AUTOSAR XML (schema 4-3-0)
standard types defined: Boolean, UInt8, SInt8, UInt16, SInt16, UInt32, SInt32, boolean, uint8, sint8, uint16, sint16, uint32, sint32
package /Components
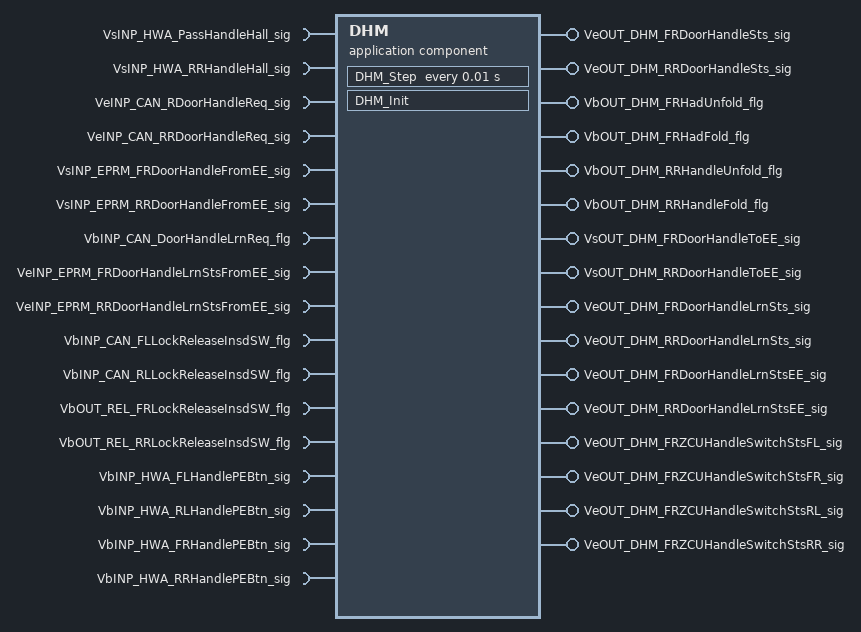
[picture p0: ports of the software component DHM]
  application sw component type DHM
    17 x require port:
      VsINP_HWA_PassHandleHall_sig: nonqueued-receiver-com-spec{data-element=VsINP_HWA_PassHandleHall_sig, init-value=0}, required-interface=VsINP_HWA_PassHandleHall_sig
      VsINP_HWA_RRHandleHall_sig: nonqueued-receiver-com-spec{data-element=VsINP_HWA_RRHandleHall_sig, init-value=0}, required-interface=VsINP_HWA_RRHandleHall_sig
      VeINP_CAN_RDoorHandleReq_sig: nonqueued-receiver-com-spec{data-element=VeINP_CAN_RDoorHandleReq_sig, init-value=0}, required-interface=VeINP_CAN_RDoorHandleReq_sig
      VeINP_CAN_RRDoorHandleReq_sig: nonqueued-receiver-com-spec{data-element=VeINP_CAN_RRDoorHandleReq_sig, init-value=0}, required-interface=VeINP_CAN_RRDoorHandleReq_sig
      VsINP_EPRM_FRDoorHandleFromEE_sig: nonqueued-receiver-com-spec{data-element=VsINP_EPRM_FRDoorHandleFromEE_sig, init-value=0}, required-interface=VsINP_EPRM_FRDoorHandleFromEE_sig
      VsINP_EPRM_RRDoorHandleFromEE_sig: nonqueued-receiver-com-spec{data-element=VsINP_EPRM_RRDoorHandleFromEE_sig, init-value=0}, required-interface=VsINP_EPRM_RRDoorHandleFromEE_sig
      VbINP_CAN_DoorHandleLrnReq_flg: nonqueued-receiver-com-spec{data-element=VbINP_CAN_DoorHandleLrnReq_flg, init-value=0}, required-interface=VbINP_CAN_DoorHandleLrnReq_flg
      VeINP_EPRM_FRDoorHandleLrnStsFromEE_sig: nonqueued-receiver-com-spec{data-element=VeINP_EPRM_FRDoorHandleLrnStsFromEE_sig, init-value=0}, required-interface=VeINP_EPRM_FRDoorHandleLrnStsFromEE_sig
      VeINP_EPRM_RRDoorHandleLrnStsFromEE_sig: nonqueued-receiver-com-spec{data-element=VeINP_EPRM_RRDoorHandleLrnStsFromEE_sig, init-value=0}, required-interface=VeINP_EPRM_RRDoorHandleLrnStsFromEE_sig
      VbINP_CAN_FLLockReleaseInsdSW_flg: nonqueued-receiver-com-spec{data-element=VbINP_CAN_FLLockReleaseInsdSW_flg, init-value=0}, required-interface=VbINP_CAN_FLLockReleaseInsdSW_flg
      VbINP_CAN_RLLockReleaseInsdSW_flg: nonqueued-receiver-com-spec{data-element=VbINP_CAN_RLLockReleaseInsdSW_flg, init-value=0}, required-interface=VbINP_CAN_RLLockReleaseInsdSW_flg
      VbOUT_REL_FRLockReleaseInsdSW_flg: nonqueued-receiver-com-spec{data-element=VbOUT_REL_FRLockReleaseInsdSW_flg, init-value=0}, required-interface=VbOUT_REL_FRLockReleaseInsdSW_flg
      VbOUT_REL_RRLockReleaseInsdSW_flg: nonqueued-receiver-com-spec{data-element=VbOUT_REL_RRLockReleaseInsdSW_flg, init-value=0}, required-interface=VbOUT_REL_RRLockReleaseInsdSW_flg
      VbINP_HWA_FLHandlePEBtn_sig: nonqueued-receiver-com-spec{data-element=VbINP_HWA_FLHandlePEBtn_sig, init-value=0}, required-interface=VbINP_HWA_FLHandlePEBtn_sig
      VbINP_HWA_RLHandlePEBtn_sig: nonqueued-receiver-com-spec{data-element=VbINP_HWA_RLHandlePEBtn_sig, init-value=0}, required-interface=VbINP_HWA_RLHandlePEBtn_sig
      VbINP_HWA_FRHandlePEBtn_sig: nonqueued-receiver-com-spec{data-element=VbINP_HWA_FRHandlePEBtn_sig, init-value=0}, required-interface=VbINP_HWA_FRHandlePEBtn_sig
      VbINP_HWA_RRHandlePEBtn_sig: nonqueued-receiver-com-spec{data-element=VbINP_HWA_RRHandlePEBtn_sig, init-value=0}, required-interface=VbINP_HWA_RRHandlePEBtn_sig
    16 x provide port:
      VeOUT_DHM_FRDoorHandleSts_sig: nonqueued-sender-com-spec{data-element=VeOUT_DHM_FRDoorHandleSts_sig, init-value=0}, provided-interface=VeOUT_DHM_FRDoorHandleSts_sig
      VeOUT_DHM_RRDoorHandleSts_sig: nonqueued-sender-com-spec{data-element=VeOUT_DHM_RRDoorHandleSts_sig, init-value=0}, provided-interface=VeOUT_DHM_RRDoorHandleSts_sig
      VbOUT_DHM_FRHadUnfold_flg: nonqueued-sender-com-spec{data-element=VbOUT_DHM_FRHadUnfold_flg, init-value=0}, provided-interface=VbOUT_DHM_FRHadUnfold_flg
      VbOUT_DHM_FRHadFold_flg: nonqueued-sender-com-spec{data-element=VbOUT_DHM_FRHadFold_flg, init-value=0}, provided-interface=VbOUT_DHM_FRHadFold_flg
      VbOUT_DHM_RRHandleUnfold_flg: nonqueued-sender-com-spec{data-element=VbOUT_DHM_RRHandleUnfold_flg, init-value=0}, provided-interface=VbOUT_DHM_RRHandleUnfold_flg
      VbOUT_DHM_RRHandleFold_flg: nonqueued-sender-com-spec{data-element=VbOUT_DHM_RRHandleFold_flg, init-value=0}, provided-interface=VbOUT_DHM_RRHandleFold_flg
      VsOUT_DHM_FRDoorHandleToEE_sig: nonqueued-sender-com-spec{data-element=VsOUT_DHM_FRDoorHandleToEE_sig, init-value=0}, provided-interface=VsOUT_DHM_FRDoorHandleToEE_sig
      VsOUT_DHM_RRDoorHandleToEE_sig: nonqueued-sender-com-spec{data-element=VsOUT_DHM_RRDoorHandleToEE_sig, init-value=0}, provided-interface=VsOUT_DHM_RRDoorHandleToEE_sig
      VeOUT_DHM_FRDoorHandleLrnSts_sig: nonqueued-sender-com-spec{data-element=VeOUT_DHM_FRDoorHandleLrnSts_sig, init-value=0}, provided-interface=VeOUT_DHM_FRDoorHandleLrnSts_sig
      VeOUT_DHM_RRDoorHandleLrnSts_sig: nonqueued-sender-com-spec{data-element=VeOUT_DHM_RRDoorHandleLrnSts_sig, init-value=0}, provided-interface=VeOUT_DHM_RRDoorHandleLrnSts_sig
      VeOUT_DHM_FRDoorHandleLrnStsEE_sig: nonqueued-sender-com-spec{data-element=VeOUT_DHM_FRDoorHandleLrnStsEE_sig, init-value=0}, provided-interface=VeOUT_DHM_FRDoorHandleLrnStsEE_sig
      VeOUT_DHM_RRDoorHandleLrnStsEE_sig: nonqueued-sender-com-spec{data-element=VeOUT_DHM_RRDoorHandleLrnStsEE_sig, init-value=0}, provided-interface=VeOUT_DHM_RRDoorHandleLrnStsEE_sig
      VeOUT_DHM_FRZCUHandleSwitchStsFL_sig: nonqueued-sender-com-spec{data-element=VeOUT_DHM_FRZCUHandleSwitchStsFL_sig, init-value=0}, provided-interface=VeOUT_DHM_FRZCUHandleSwitchStsFL_sig
      VeOUT_DHM_FRZCUHandleSwitchStsFR_sig: nonqueued-sender-com-spec{data-element=VeOUT_DHM_FRZCUHandleSwitchStsFR_sig, init-value=0}, provided-interface=VeOUT_DHM_FRZCUHandleSwitchStsFR_sig
      VeOUT_DHM_FRZCUHandleSwitchStsRL_sig: nonqueued-sender-com-spec{data-element=VeOUT_DHM_FRZCUHandleSwitchStsRL_sig, init-value=0}, provided-interface=VeOUT_DHM_FRZCUHandleSwitchStsRL_sig
      VeOUT_DHM_FRZCUHandleSwitchStsRR_sig: nonqueued-sender-com-spec{data-element=VeOUT_DHM_FRZCUHandleSwitchStsRR_sig, init-value=0}, provided-interface=VeOUT_DHM_FRZCUHandleSwitchStsRR_sig
    behavior DHM: data-type-mapping=DataTypeMappingsSet, handle-termination-and-restart=NO-SUPPORT
      init event DHM_InitEvent: start-on-event=DHM_Init
      timing event Event_Runnable_Step: start-on-event=DHM_Step, period=0.01
      runnable DHM_Init
      runnable DHM_Step
        data-receive-point-by-arguments:
          17 x access:
            IN_VsINP_HWA_PassHandleHall_sig_VsINP_HWA_PassHandleHall_sig: accessed-variable=VsINP_HWA_PassHandleHall_sig.VsINP_HWA_PassHandleHall_sig
            IN_VsINP_HWA_RRHandleHall_sig_VsINP_HWA_RRHandleHall_sig: accessed-variable=VsINP_HWA_RRHandleHall_sig.VsINP_HWA_RRHandleHall_sig
            IN_VeINP_CAN_RDoorHandleReq_sig_VeINP_CAN_RDoorHandleReq_sig: accessed-variable=VeINP_CAN_RDoorHandleReq_sig.VeINP_CAN_RDoorHandleReq_sig
            IN_VeINP_CAN_RRDoorHandleReq_sig_VeINP_CAN_RRDoorHandleReq_sig: accessed-variable=VeINP_CAN_RRDoorHandleReq_sig.VeINP_CAN_RRDoorHandleReq_sig
            IN_VsINP_EPRM_FRDoorHandleFromEE_sig_VsINP_EPRM_FRDoorHandleFromEE_sig: accessed-variable=VsINP_EPRM_FRDoorHandleFromEE_sig.VsINP_EPRM_FRDoorHandleFromEE_sig
            IN_VsINP_EPRM_RRDoorHandleFromEE_sig_VsINP_EPRM_RRDoorHandleFromEE_sig: accessed-variable=VsINP_EPRM_RRDoorHandleFromEE_sig.VsINP_EPRM_RRDoorHandleFromEE_sig
            IN_VbINP_CAN_DoorHandleLrnReq_flg_VbINP_CAN_DoorHandleLrnReq_flg: accessed-variable=VbINP_CAN_DoorHandleLrnReq_flg.VbINP_CAN_DoorHandleLrnReq_flg
            IN_VeINP_EPRM_FRDoorHandleLrnStsFromEE_sig_VeINP_EPRM_FRDoorHandleLrnStsFromEE_sig: accessed-variable=VeINP_EPRM_FRDoorHandleLrnStsFromEE_sig.VeINP_EPRM_FRDoorHandleLrnStsFromEE_sig
            IN_VeINP_EPRM_RRDoorHandleLrnStsFromEE_sig_VeINP_EPRM_RRDoorHandleLrnStsFromEE_sig: accessed-variable=VeINP_EPRM_RRDoorHandleLrnStsFromEE_sig.VeINP_EPRM_RRDoorHandleLrnStsFromEE_sig
            IN_VbINP_CAN_FLLockReleaseInsdSW_flg_VbINP_CAN_FLLockReleaseInsdSW_flg: accessed-variable=VbINP_CAN_FLLockReleaseInsdSW_flg.VbINP_CAN_FLLockReleaseInsdSW_flg
            IN_VbINP_CAN_RLLockReleaseInsdSW_flg_VbINP_CAN_RLLockReleaseInsdSW_flg: accessed-variable=VbINP_CAN_RLLockReleaseInsdSW_flg.VbINP_CAN_RLLockReleaseInsdSW_flg
            IN_VbOUT_REL_FRLockReleaseInsdSW_flg_VbOUT_REL_FRLockReleaseInsdSW_flg: accessed-variable=VbOUT_REL_FRLockReleaseInsdSW_flg.VbOUT_REL_FRLockReleaseInsdSW_flg
            IN_VbOUT_REL_RRLockReleaseInsdSW_flg_VbOUT_REL_RRLockReleaseInsdSW_flg: accessed-variable=VbOUT_REL_RRLockReleaseInsdSW_flg.VbOUT_REL_RRLockReleaseInsdSW_flg
            IN_VbINP_HWA_FLHandlePEBtn_sig_VbINP_HWA_FLHandlePEBtn_sig: accessed-variable=VbINP_HWA_FLHandlePEBtn_sig.VbINP_HWA_FLHandlePEBtn_sig
            IN_VbINP_HWA_RLHandlePEBtn_sig_VbINP_HWA_RLHandlePEBtn_sig: accessed-variable=VbINP_HWA_RLHandlePEBtn_sig.VbINP_HWA_RLHandlePEBtn_sig
            IN_VbINP_HWA_FRHandlePEBtn_sig_VbINP_HWA_FRHandlePEBtn_sig: accessed-variable=VbINP_HWA_FRHandlePEBtn_sig.VbINP_HWA_FRHandlePEBtn_sig
            IN_VbINP_HWA_RRHandlePEBtn_sig_VbINP_HWA_RRHandlePEBtn_sig: accessed-variable=VbINP_HWA_RRHandlePEBtn_sig.VbINP_HWA_RRHandlePEBtn_sig
        data-send-points:
          16 x access:
            OUT_VeOUT_DHM_FRDoorHandleSts_sig_VeOUT_DHM_FRDoorHandleSts_sig: accessed-variable=VeOUT_DHM_FRDoorHandleSts_sig.VeOUT_DHM_FRDoorHandleSts_sig
            OUT_VeOUT_DHM_RRDoorHandleSts_sig_VeOUT_DHM_RRDoorHandleSts_sig: accessed-variable=VeOUT_DHM_RRDoorHandleSts_sig.VeOUT_DHM_RRDoorHandleSts_sig
            OUT_VbOUT_DHM_FRHadUnfold_flg_VbOUT_DHM_FRHadUnfold_flg: accessed-variable=VbOUT_DHM_FRHadUnfold_flg.VbOUT_DHM_FRHadUnfold_flg
            OUT_VbOUT_DHM_FRHadFold_flg_VbOUT_DHM_FRHadFold_flg: accessed-variable=VbOUT_DHM_FRHadFold_flg.VbOUT_DHM_FRHadFold_flg
            OUT_VbOUT_DHM_RRHandleUnfold_flg_VbOUT_DHM_RRHandleUnfold_flg: accessed-variable=VbOUT_DHM_RRHandleUnfold_flg.VbOUT_DHM_RRHandleUnfold_flg
            OUT_VbOUT_DHM_RRHandleFold_flg_VbOUT_DHM_RRHandleFold_flg: accessed-variable=VbOUT_DHM_RRHandleFold_flg.VbOUT_DHM_RRHandleFold_flg
            OUT_VsOUT_DHM_FRDoorHandleToEE_sig_VsOUT_DHM_FRDoorHandleToEE_sig: accessed-variable=VsOUT_DHM_FRDoorHandleToEE_sig.VsOUT_DHM_FRDoorHandleToEE_sig
            OUT_VsOUT_DHM_RRDoorHandleToEE_sig_VsOUT_DHM_RRDoorHandleToEE_sig: accessed-variable=VsOUT_DHM_RRDoorHandleToEE_sig.VsOUT_DHM_RRDoorHandleToEE_sig
            OUT_VeOUT_DHM_FRDoorHandleLrnSts_sig_VeOUT_DHM_FRDoorHandleLrnSts_sig: accessed-variable=VeOUT_DHM_FRDoorHandleLrnSts_sig.VeOUT_DHM_FRDoorHandleLrnSts_sig
            OUT_VeOUT_DHM_RRDoorHandleLrnSts_sig_VeOUT_DHM_RRDoorHandleLrnSts_sig: accessed-variable=VeOUT_DHM_RRDoorHandleLrnSts_sig.VeOUT_DHM_RRDoorHandleLrnSts_sig
            OUT_VeOUT_DHM_FRDoorHandleLrnStsEE_sig_VeOUT_DHM_FRDoorHandleLrnStsEE_sig: accessed-variable=VeOUT_DHM_FRDoorHandleLrnStsEE_sig.VeOUT_DHM_FRDoorHandleLrnStsEE_sig
            OUT_VeOUT_DHM_RRDoorHandleLrnStsEE_sig_VeOUT_DHM_RRDoorHandleLrnStsEE_sig: accessed-variable=VeOUT_DHM_RRDoorHandleLrnStsEE_sig.VeOUT_DHM_RRDoorHandleLrnStsEE_sig
            OUT_VeOUT_DHM_FRZCUHandleSwitchStsFL_sig_VeOUT_DHM_FRZCUHandleSwitchStsFL_sig: accessed-variable=VeOUT_DHM_FRZCUHandleSwitchStsFL_sig.VeOUT_DHM_FRZCUHandleSwitchStsFL_sig
            OUT_VeOUT_DHM_FRZCUHandleSwitchStsFR_sig_VeOUT_DHM_FRZCUHandleSwitchStsFR_sig: accessed-variable=VeOUT_DHM_FRZCUHandleSwitchStsFR_sig.VeOUT_DHM_FRZCUHandleSwitchStsFR_sig
            OUT_VeOUT_DHM_FRZCUHandleSwitchStsRL_sig_VeOUT_DHM_FRZCUHandleSwitchStsRL_sig: accessed-variable=VeOUT_DHM_FRZCUHandleSwitchStsRL_sig.VeOUT_DHM_FRZCUHandleSwitchStsRL_sig
            OUT_VeOUT_DHM_FRZCUHandleSwitchStsRR_sig_VeOUT_DHM_FRZCUHandleSwitchStsRR_sig: accessed-variable=VeOUT_DHM_FRZCUHandleSwitchStsRR_sig.VeOUT_DHM_FRZCUHandleSwitchStsRR_sig
package /Interfaces
  33 x sender receiver interface:
    VsINP_HWA_PassHandleHall_sig
      data VsINP_HWA_PassHandleHall_sig: category=VALUE, sw-calibration-access=READ-ONLY, type=SInt16
    VsINP_HWA_RRHandleHall_sig
      data VsINP_HWA_RRHandleHall_sig: category=VALUE, sw-calibration-access=READ-ONLY, type=SInt16
    VeINP_CAN_RDoorHandleReq_sig
      data VeINP_CAN_RDoorHandleReq_sig: category=VALUE, sw-calibration-access=READ-ONLY, type=UInt8
    VeINP_CAN_RRDoorHandleReq_sig
      data VeINP_CAN_RRDoorHandleReq_sig: category=VALUE, sw-calibration-access=READ-ONLY, type=UInt8
    VsINP_EPRM_FRDoorHandleFromEE_sig
      data VsINP_EPRM_FRDoorHandleFromEE_sig: category=VALUE, sw-calibration-access=READ-ONLY, type=SInt16
    VsINP_EPRM_RRDoorHandleFromEE_sig
      data VsINP_EPRM_RRDoorHandleFromEE_sig: category=VALUE, sw-calibration-access=READ-ONLY, type=SInt16
    VbINP_CAN_DoorHandleLrnReq_flg
      data VbINP_CAN_DoorHandleLrnReq_flg: category=BOOLEAN, sw-calibration-access=READ-ONLY, type=Boolean
    VeINP_EPRM_FRDoorHandleLrnStsFromEE_sig
      data VeINP_EPRM_FRDoorHandleLrnStsFromEE_sig: category=VALUE, sw-calibration-access=READ-ONLY, type=UInt8
    VeINP_EPRM_RRDoorHandleLrnStsFromEE_sig
      data VeINP_EPRM_RRDoorHandleLrnStsFromEE_sig: category=VALUE, sw-calibration-access=READ-ONLY, type=UInt8
    VbINP_CAN_FLLockReleaseInsdSW_flg
      data VbINP_CAN_FLLockReleaseInsdSW_flg: category=BOOLEAN, sw-calibration-access=READ-ONLY, type=Boolean
    VbINP_CAN_RLLockReleaseInsdSW_flg
      data VbINP_CAN_RLLockReleaseInsdSW_flg: category=BOOLEAN, sw-calibration-access=READ-ONLY, type=Boolean
    VbOUT_REL_FRLockReleaseInsdSW_flg
      data VbOUT_REL_FRLockReleaseInsdSW_flg: category=BOOLEAN, sw-calibration-access=READ-ONLY, type=Boolean
    VbOUT_REL_RRLockReleaseInsdSW_flg
      data VbOUT_REL_RRLockReleaseInsdSW_flg: category=BOOLEAN, sw-calibration-access=READ-ONLY, type=Boolean
    VbINP_HWA_FLHandlePEBtn_sig
      data VbINP_HWA_FLHandlePEBtn_sig: category=BOOLEAN, sw-calibration-access=READ-ONLY, type=Boolean
    VbINP_HWA_RLHandlePEBtn_sig
      data VbINP_HWA_RLHandlePEBtn_sig: category=BOOLEAN, sw-calibration-access=READ-ONLY, type=Boolean
    VbINP_HWA_FRHandlePEBtn_sig
      data VbINP_HWA_FRHandlePEBtn_sig: category=BOOLEAN, sw-calibration-access=READ-ONLY, type=Boolean
    VbINP_HWA_RRHandlePEBtn_sig
      data VbINP_HWA_RRHandlePEBtn_sig: category=BOOLEAN, sw-calibration-access=READ-ONLY, type=Boolean
    VeOUT_DHM_FRDoorHandleSts_sig
      data VeOUT_DHM_FRDoorHandleSts_sig: category=VALUE, sw-calibration-access=READ-ONLY, type=UInt8
    VeOUT_DHM_RRDoorHandleSts_sig
      data VeOUT_DHM_RRDoorHandleSts_sig: category=VALUE, sw-calibration-access=READ-ONLY, type=UInt8
    VbOUT_DHM_FRHadUnfold_flg
      data VbOUT_DHM_FRHadUnfold_flg: category=BOOLEAN, sw-calibration-access=READ-ONLY, type=Boolean
    VbOUT_DHM_FRHadFold_flg
      data VbOUT_DHM_FRHadFold_flg: category=BOOLEAN, sw-calibration-access=READ-ONLY, type=Boolean
    VbOUT_DHM_RRHandleUnfold_flg
      data VbOUT_DHM_RRHandleUnfold_flg: category=BOOLEAN, sw-calibration-access=READ-ONLY, type=Boolean
    VbOUT_DHM_RRHandleFold_flg
      data VbOUT_DHM_RRHandleFold_flg: category=BOOLEAN, sw-calibration-access=READ-ONLY, type=Boolean
    VsOUT_DHM_FRDoorHandleToEE_sig
      data VsOUT_DHM_FRDoorHandleToEE_sig: category=VALUE, sw-calibration-access=READ-ONLY, type=SInt16
    VsOUT_DHM_RRDoorHandleToEE_sig
      data VsOUT_DHM_RRDoorHandleToEE_sig: category=VALUE, sw-calibration-access=READ-ONLY, type=SInt16
    VeOUT_DHM_FRDoorHandleLrnSts_sig
      data VeOUT_DHM_FRDoorHandleLrnSts_sig: category=VALUE, sw-calibration-access=READ-ONLY, type=UInt8
    VeOUT_DHM_RRDoorHandleLrnSts_sig
      data VeOUT_DHM_RRDoorHandleLrnSts_sig: category=VALUE, sw-calibration-access=READ-ONLY, type=UInt8
    VeOUT_DHM_FRDoorHandleLrnStsEE_sig
      data VeOUT_DHM_FRDoorHandleLrnStsEE_sig: category=VALUE, sw-calibration-access=READ-ONLY, type=UInt8
    VeOUT_DHM_RRDoorHandleLrnStsEE_sig
      data VeOUT_DHM_RRDoorHandleLrnStsEE_sig: category=VALUE, sw-calibration-access=READ-ONLY, type=UInt8
    VeOUT_DHM_FRZCUHandleSwitchStsFL_sig
      data VeOUT_DHM_FRZCUHandleSwitchStsFL_sig: category=VALUE, sw-calibration-access=READ-ONLY, type=UInt8
    VeOUT_DHM_FRZCUHandleSwitchStsFR_sig
      data VeOUT_DHM_FRZCUHandleSwitchStsFR_sig: category=VALUE, sw-calibration-access=READ-ONLY, type=UInt8
    VeOUT_DHM_FRZCUHandleSwitchStsRL_sig
      data VeOUT_DHM_FRZCUHandleSwitchStsRL_sig: category=VALUE, sw-calibration-access=READ-ONLY, type=UInt8
    VeOUT_DHM_FRZCUHandleSwitchStsRR_sig
      data VeOUT_DHM_FRZCUHandleSwitchStsRR_sig: category=VALUE, sw-calibration-access=READ-ONLY, type=UInt8
package /DHM_imp
  swc implementation DHM: behavior=DHM
    code-descriptors:
      code Default: artifact-descriptors=autosar-engineering-object={short-label=Default, category=SWSRC}
package /DataTypes/SwAddrMethods
  sw addr method CODE: section-type=CODE
  sw addr method CONST: section-type=CONST
  sw addr method VAR: section-type=VAR
package /DataTypes/ApplicationDataTypes
  7 x app type, all with sw-calibration-access=READ-WRITE:
    Boolean: category=BOOLEAN, compu {0=FALSE, 1=TRUE}
    UInt8: category=VALUE, compu {identical}, range phys 0..255
    SInt8: category=VALUE, compu {identical}, range phys -128..127
    UInt16: category=VALUE, compu {identical}, range phys 0..65535
    SInt16: category=VALUE, compu {identical}, range phys -32768..32767
    UInt32: category=VALUE, compu {identical}, range phys 0..4294967295
    SInt32: category=VALUE, compu {identical}, range phys -2147483648..2147483647
  application array data type rt_Array_UInt8_20: category=ARRAY, sw-calibration-access=READ-WRITE
    element rt_Array_UInt8_20: category=VALUE, type=UInt8, array-size-semantics=FIXED-SIZE, max-number-of-elements=20
package /DataTypes/ImplementationDataTypes
  impl type rt_Array_UInt8_20: category=ARRAY
    element rt_Array_UInt8_20: array-size=20, array-size-semantics=FIXED-SIZE, implementation-data-type=UInt8
package /DataTypes/Units
  unit NoUnit: factor-si-to-unit=1, offset-si-to-unit=0
package /DataTypes/DataTypeMappings
  data type mapping set DataTypeMappingsSet
    data-type-maps:
      application-data-type=Boolean, implementation-data-type=Boolean
      application-data-type=UInt8, implementation-data-type=UInt8
      application-data-type=SInt8, implementation-data-type=SInt8
      application-data-type=UInt16, implementation-data-type=UInt16
      application-data-type=SInt16, implementation-data-type=SInt16
      application-data-type=UInt32, implementation-data-type=UInt32
      application-data-type=SInt32, implementation-data-type=SInt32
      application-data-type=rt_Array_UInt8_20, implementation-data-type=rt_Array_UInt8_20
